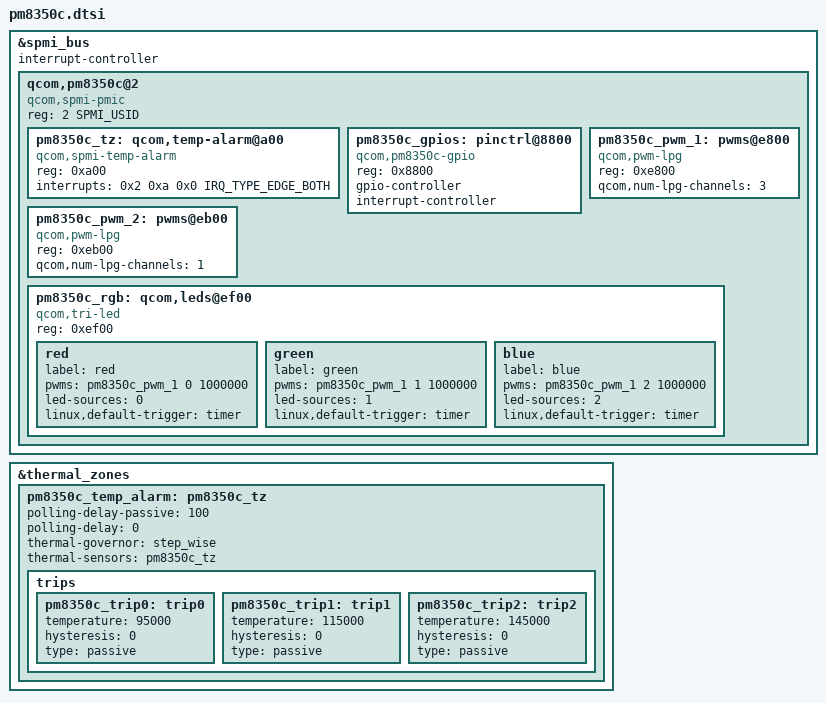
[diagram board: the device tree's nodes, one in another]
#include <dt-bindings/interrupt-controller/irq.h>
#include <dt-bindings/spmi/spmi.h>

&spmi_bus {
	#address-cells = <2>;
	#size-cells = <0>;
	interrupt-controller;
	#interrupt-cells = <4>;

	qcom,pm8350c@2 {
		compatible = "qcom,spmi-pmic";
		reg = <2 SPMI_USID>;
		#address-cells = <1>;
		#size-cells = <0>;

		pm8350c_tz: qcom,temp-alarm@a00 {
			compatible = "qcom,spmi-temp-alarm";
			reg = <0xa00>;
			interrupts = <0x2 0xa 0x0 IRQ_TYPE_EDGE_BOTH>;
			#thermal-sensor-cells = <0>;
		};

		pm8350c_gpios: pinctrl@8800 {
			compatible = "qcom,pm8350c-gpio";
			reg = <0x8800>;
			gpio-controller;
			#gpio-cells = <2>;
			interrupt-controller;
			#interrupt-cells = <2>;
		};

		pm8350c_pwm_1: pwms@e800 {
			compatible = "qcom,pwm-lpg";
			reg = <0xe800>;
			reg-names = "lpg-base";
			#pwm-cells = <2>;
			qcom,num-lpg-channels = <3>;
		};

		pm8350c_pwm_2: pwms@eb00 {
			compatible = "qcom,pwm-lpg";
			reg = <0xeb00>;
			reg-names = "lpg-base";
			#pwm-cells = <2>;
			qcom,num-lpg-channels = <1>;
		};

		pm8350c_rgb: qcom,leds@ef00 {
			compatible = "qcom,tri-led";
			reg = <0xef00>;

			red {
				label = "red";
				pwms = <&pm8350c_pwm_1 0 1000000>;
				led-sources = <0>;
				linux,default-trigger = "timer";
			};

			green {
				label = "green";
				pwms = <&pm8350c_pwm_1 1 1000000>;
				led-sources = <1>;
				linux,default-trigger = "timer";
			};

			blue {
				label = "blue";
				pwms = <&pm8350c_pwm_1 2 1000000>;
				led-sources = <2>;
				linux,default-trigger = "timer";
			};
		};
	};
};

&thermal_zones {
	pm8350c_temp_alarm: pm8350c_tz {
		polling-delay-passive = <100>;
		polling-delay = <0>;
		thermal-governor = "step_wise";
		thermal-sensors = <&pm8350c_tz>;

		trips {
			pm8350c_trip0: trip0 {
				temperature = <95000>;
				hysteresis = <0>;
				type = "passive";
			};

			pm8350c_trip1: trip1 {
				temperature = <115000>;
				hysteresis = <0>;
				type = "passive";
			};

			pm8350c_trip2: trip2 {
				temperature = <145000>;
				hysteresis = <0>;
				type = "passive";
			};
		};
	};
};
